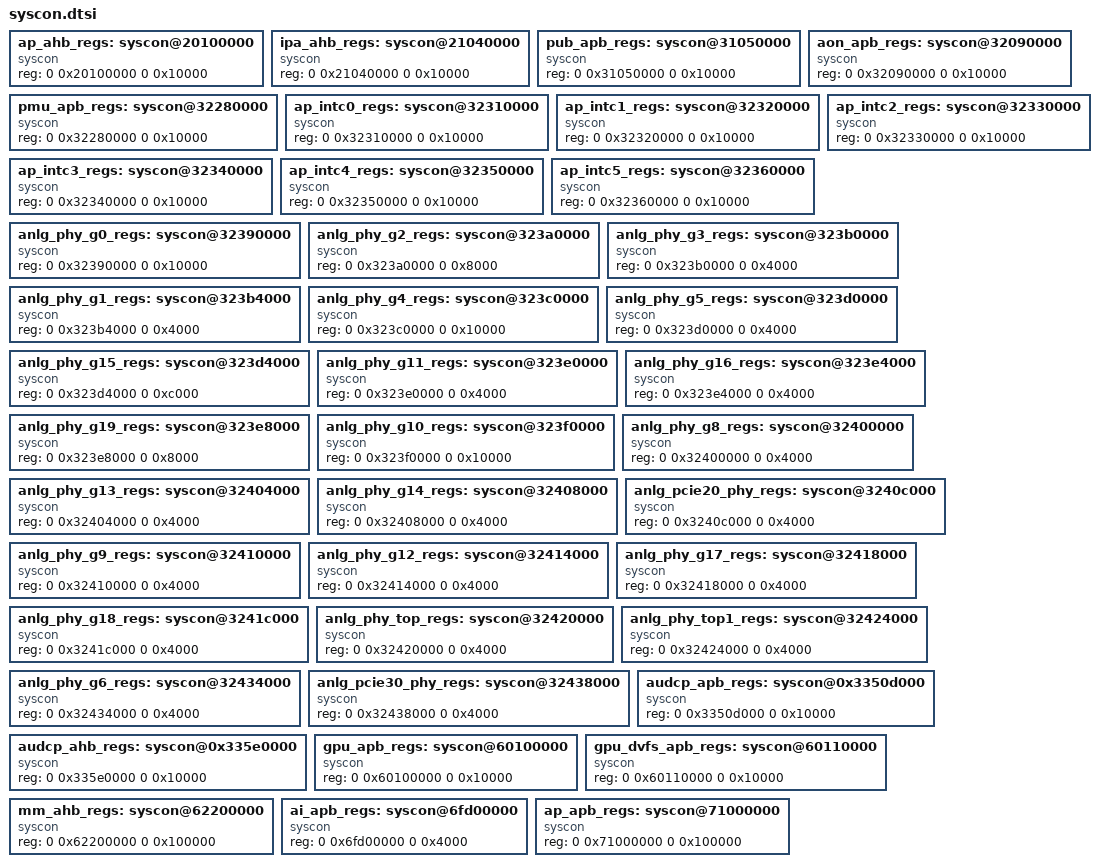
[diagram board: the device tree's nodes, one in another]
/*
 * Spreadtrum Roc1 platform DTS file
 *
 * Copyright (C) 2018, Spreadtrum Communications Inc.
 *
 * This file is licensed under a dual GPLv2 or X11 license.
 */

		ap_ahb_regs: syscon@20100000 {
			compatible = "syscon";
			#syscon-cells = <2>;
			reg = <0 0x20100000 0 0x10000>;
		};

		ipa_ahb_regs: syscon@21040000 {
			compatible = "syscon";
			#syscon-cells = <2>;
			reg = <0 0x21040000 0 0x10000>;
		};

		pub_apb_regs: syscon@31050000 {
			compatible = "syscon";
			#syscon-cells = <2>;
			reg = <0 0x31050000 0 0x10000>;
		};

		aon_apb_regs: syscon@32090000 {
			compatible = "syscon";
			#syscon-cells = <2>;
			reg = <0 0x32090000 0 0x10000>;
		};

		pmu_apb_regs: syscon@32280000 {
			compatible = "syscon";
			#syscon-cells = <2>;
			reg = <0 0x32280000 0 0x10000>;
		};

		ap_intc0_regs: syscon@32310000 {
			compatible = "syscon";
			#syscon-cells = <2>;
			reg = <0 0x32310000 0 0x10000>;
		};

		ap_intc1_regs: syscon@32320000 {
			compatible = "syscon";
			#syscon-cells = <2>;
			reg = <0 0x32320000 0 0x10000>;
		};

		ap_intc2_regs: syscon@32330000 {
			compatible = "syscon";
			#syscon-cells = <2>;
			reg = <0 0x32330000 0 0x10000>;
		};

		ap_intc3_regs: syscon@32340000 {
			compatible = "syscon";
			#syscon-cells = <2>;
			reg = <0 0x32340000 0 0x10000>;
		};

		ap_intc4_regs: syscon@32350000 {
			compatible = "syscon";
			#syscon-cells = <2>;
			reg = <0 0x32350000 0 0x10000>;
		};

		ap_intc5_regs: syscon@32360000 {
			compatible = "syscon";
			#syscon-cells = <2>;
			reg = <0 0x32360000 0 0x10000>;
		};

		anlg_phy_g0_regs: syscon@32390000 {
			compatible = "syscon";
			#syscon-cells = <2>;
			reg = <0 0x32390000 0 0x10000>;
		};

		anlg_phy_g2_regs: syscon@323a0000 {
			compatible = "syscon";
			#syscon-cells = <2>;
			reg = <0 0x323a0000 0 0x8000>;
		};

		anlg_phy_g3_regs: syscon@323b0000 {
			compatible = "syscon";
			#syscon-cells = <2>;
			reg = <0 0x323b0000 0 0x4000>;
		};

		anlg_phy_g1_regs: syscon@323b4000 {
			compatible = "syscon";
			#syscon-cells = <2>;
			reg = <0 0x323b4000 0 0x4000>;
		};

		anlg_phy_g4_regs: syscon@323c0000 {
			compatible = "syscon";
			#syscon-cells = <2>;
			reg = <0 0x323c0000 0 0x10000>;
		};

		anlg_phy_g5_regs: syscon@323d0000 {
			compatible = "syscon";
			#syscon-cells = <2>;
			reg = <0 0x323d0000 0 0x4000>;
		};

		anlg_phy_g15_regs: syscon@323d4000 {
			compatible = "syscon";
			#syscon-cells = <2>;
			reg = <0 0x323d4000 0 0xc000>;
		};

		anlg_phy_g11_regs: syscon@323e0000 {
			compatible = "syscon";
			#syscon-cells = <2>;
			reg = <0 0x323e0000 0 0x4000>;
		};

		anlg_phy_g16_regs: syscon@323e4000 {
			compatible = "syscon";
			#syscon-cells = <2>;
			reg = <0 0x323e4000 0 0x4000>;
		};

		anlg_phy_g19_regs: syscon@323e8000 {
			compatible = "syscon";
			#syscon-cells = <2>;
			reg = <0 0x323e8000 0 0x8000>;
		};

		anlg_phy_g10_regs: syscon@323f0000 {
			compatible = "syscon";
			#syscon-cells = <2>;
			reg = <0 0x323f0000 0 0x10000>;
		};

		anlg_phy_g8_regs: syscon@32400000 {
			compatible = "syscon";
			#syscon-cells = <2>;
			reg = <0 0x32400000 0 0x4000>;
		};

		anlg_phy_g13_regs: syscon@32404000 {
			compatible = "syscon";
			#syscon-cells = <2>;
			reg = <0 0x32404000 0 0x4000>;
		};

		anlg_phy_g14_regs: syscon@32408000 {
			compatible = "syscon";
			#syscon-cells = <2>;
			reg = <0 0x32408000 0 0x4000>;
		};

		anlg_pcie20_phy_regs: syscon@3240c000 {
			compatible = "syscon";
			#syscon-cells = <2>;
			reg = <0 0x3240c000 0 0x4000>;
		};

		anlg_phy_g9_regs: syscon@32410000 {
			compatible = "syscon";
			#syscon-cells = <2>;
			reg = <0 0x32410000 0 0x4000>;
		};

		anlg_phy_g12_regs: syscon@32414000 {
			compatible = "syscon";
			#syscon-cells = <2>;
			reg = <0 0x32414000 0 0x4000>;
		};

		anlg_phy_g17_regs: syscon@32418000 {
			compatible = "syscon";
			#syscon-cells = <2>;
			reg = <0 0x32418000 0 0x4000>;
		};

		anlg_phy_g18_regs: syscon@3241c000 {
			compatible = "syscon";
			#syscon-cells = <2>;
			reg = <0 0x3241c000 0 0x4000>;
		};

		anlg_phy_top_regs: syscon@32420000 {
			compatible = "syscon";
			#syscon-cells = <2>;
			reg = <0 0x32420000 0 0x4000>;
		};

		anlg_phy_top1_regs: syscon@32424000 {
			compatible = "syscon";
			#syscon-cells = <2>;
			reg = <0 0x32424000 0 0x4000>;
		};

		anlg_phy_g6_regs: syscon@32434000 {
			compatible = "syscon";
			#syscon-cells = <2>;
			reg = <0 0x32434000 0 0x4000>;
		};

		anlg_pcie30_phy_regs: syscon@32438000 {
			compatible = "syscon";
			#syscon-cells = <2>;
			reg = <0 0x32438000 0 0x4000>;
		};

		audcp_apb_regs: syscon@0x3350d000 {
			compatible = "syscon";
			#syscon-cells = <2>;
			reg = <0 0x3350d000 0 0x10000>;
		};

		audcp_ahb_regs: syscon@0x335e0000 {
			compatible = "syscon";
			#syscon-cells = <2>;
			reg = <0 0x335e0000 0 0x10000>;
		};

		gpu_apb_regs: syscon@60100000 {
			compatible = "syscon";
			#syscon-cells = <2>;
			reg = <0 0x60100000 0 0x10000>;
		};

		gpu_dvfs_apb_regs: syscon@60110000 {
			compatible = "syscon";
			#syscon-cells = <2>;
			reg = <0 0x60110000 0 0x10000>;
		};

		mm_ahb_regs: syscon@62200000 {
			compatible = "syscon";
			#syscon-cells = <2>;
			reg = <0 0x62200000 0 0x100000>;
		};

		ai_apb_regs: syscon@6fd00000 {
			compatible = "syscon";
			#syscon-cells = <2>;
			reg = <0 0x6fd00000 0 0x4000>;
		};

		ap_apb_regs: syscon@71000000 {
			compatible = "syscon";
			#syscon-cells = <2>;
			reg = <0 0x71000000 0 0x100000>;
		};

